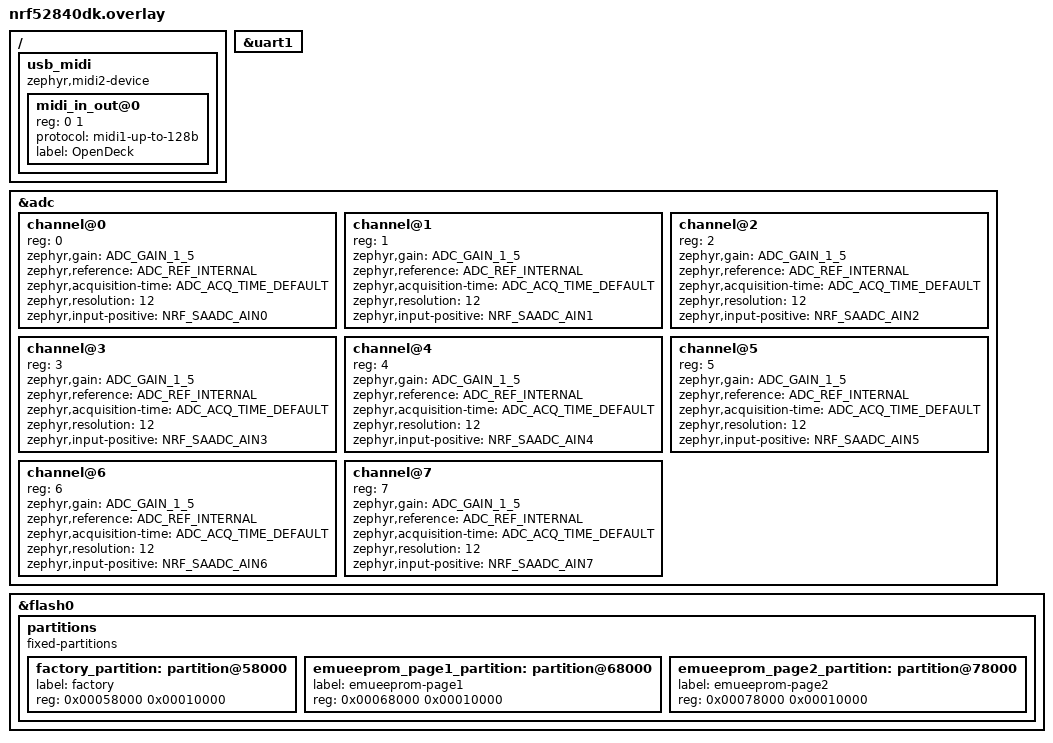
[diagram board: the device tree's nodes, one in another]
/ {
    usb_midi: usb_midi {
        compatible = "zephyr,midi2-device";
        status = "okay";
        #address-cells = <1>;
        #size-cells = <1>;

        midi_in_out@0 {
            reg = <0 1>;
            protocol = "midi1-up-to-128b";
            label = "OpenDeck";
        };
    };
};

&uart1 {
    status = "okay";
};

&adc {
    status = "okay";
    #address-cells = <1>;
    #size-cells = <0>;

    channel@0 {
        reg = <0>;
        zephyr,gain = "ADC_GAIN_1_5";
        zephyr,reference = "ADC_REF_INTERNAL";
        zephyr,acquisition-time = <ADC_ACQ_TIME_DEFAULT>;
        zephyr,resolution = <12>;
        zephyr,input-positive = <NRF_SAADC_AIN0>;
    };

    channel@1 {
        reg = <1>;
        zephyr,gain = "ADC_GAIN_1_5";
        zephyr,reference = "ADC_REF_INTERNAL";
        zephyr,acquisition-time = <ADC_ACQ_TIME_DEFAULT>;
        zephyr,resolution = <12>;
        zephyr,input-positive = <NRF_SAADC_AIN1>;
    };

    channel@2 {
        reg = <2>;
        zephyr,gain = "ADC_GAIN_1_5";
        zephyr,reference = "ADC_REF_INTERNAL";
        zephyr,acquisition-time = <ADC_ACQ_TIME_DEFAULT>;
        zephyr,resolution = <12>;
        zephyr,input-positive = <NRF_SAADC_AIN2>;
    };

    channel@3 {
        reg = <3>;
        zephyr,gain = "ADC_GAIN_1_5";
        zephyr,reference = "ADC_REF_INTERNAL";
        zephyr,acquisition-time = <ADC_ACQ_TIME_DEFAULT>;
        zephyr,resolution = <12>;
        zephyr,input-positive = <NRF_SAADC_AIN3>;
    };

    channel@4 {
        reg = <4>;
        zephyr,gain = "ADC_GAIN_1_5";
        zephyr,reference = "ADC_REF_INTERNAL";
        zephyr,acquisition-time = <ADC_ACQ_TIME_DEFAULT>;
        zephyr,resolution = <12>;
        zephyr,input-positive = <NRF_SAADC_AIN4>;
    };

    channel@5 {
        reg = <5>;
        zephyr,gain = "ADC_GAIN_1_5";
        zephyr,reference = "ADC_REF_INTERNAL";
        zephyr,acquisition-time = <ADC_ACQ_TIME_DEFAULT>;
        zephyr,resolution = <12>;
        zephyr,input-positive = <NRF_SAADC_AIN5>;
    };

    channel@6 {
        reg = <6>;
        zephyr,gain = "ADC_GAIN_1_5";
        zephyr,reference = "ADC_REF_INTERNAL";
        zephyr,acquisition-time = <ADC_ACQ_TIME_DEFAULT>;
        zephyr,resolution = <12>;
        zephyr,input-positive = <NRF_SAADC_AIN6>;
    };

    channel@7 {
        reg = <7>;
        zephyr,gain = "ADC_GAIN_1_5";
        zephyr,reference = "ADC_REF_INTERNAL";
        zephyr,acquisition-time = <ADC_ACQ_TIME_DEFAULT>;
        zephyr,resolution = <12>;
        zephyr,input-positive = <NRF_SAADC_AIN7>;
    };
};

&flash0 {
    partitions {
        compatible = "fixed-partitions";
        #address-cells = <1>;
        #size-cells = <1>;

        factory_partition: partition@58000 {
            label = "factory";
            reg = <0x00058000 0x00010000>;
        };

        emueeprom_page1_partition: partition@68000 {
            label = "emueeprom-page1";
            reg = <0x00068000 0x00010000>;
        };

        emueeprom_page2_partition: partition@78000 {
            label = "emueeprom-page2";
            reg = <0x00078000 0x00010000>;
        };
    };
};
